# nrf5002 register map
Vendor: Nordic Semiconductor; Series: nRF50; File version: 1
CPU: CM0 r0p4, little endian, no MPU, no FPU, 2 interrupt priority bits, 32 interrupts
Registers are 32-bit, read-write, reset 0x0 unless marked. A register's access mark holds for its fields unless they carry their own. Offsets are from the block's base; [hi:lo] are bit positions; 'fields as' and 'values as' point back to an identical list.

## CCM — AES CCM mode encryption
Base 0x4000A000
0x00 TASKS_KSGEN wo — Start generation of keystream. This operation will stop by itself when completed.
  [0] TASKS_KSGEN
    1=Trigger task
0x04 TASKS_CRYPT wo — Start encryption/decryption. This operation will stop by itself when completed.
  [0] TASKS_CRYPT
    1=Trigger task
0x08 TASKS_STOP wo — Stop encryption/decryption
  [0] TASKS_STOP
    1=Trigger task
0x0C TASKS_RATEOVERRIDE wo — Override DATARATE setting in MODE register with the contents of the RATEOVERRIDE register for any ongoing encryption/decryption
  [0] TASKS_RATEOVERRIDE
    1=Trigger task
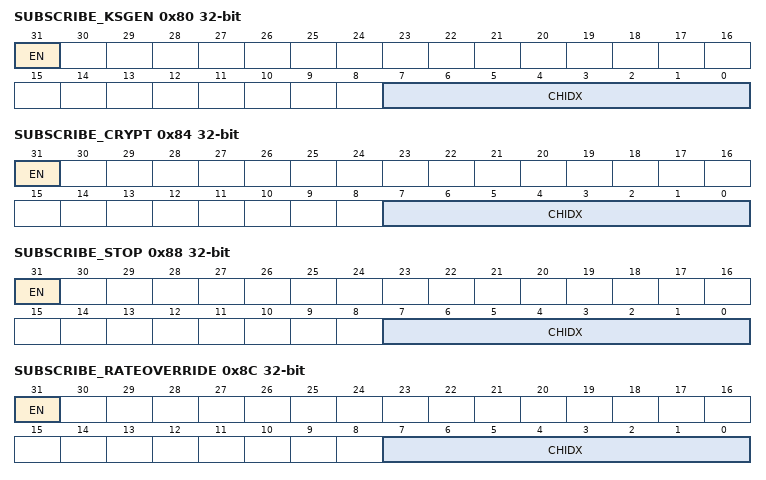
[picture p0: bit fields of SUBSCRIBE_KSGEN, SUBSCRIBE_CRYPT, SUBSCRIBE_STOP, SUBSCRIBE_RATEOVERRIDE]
0x80 SUBSCRIBE_KSGEN — Subscribe configuration for task KSGEN
  [31] EN
    0=Disabled (Disable subscription); 1=Enabled (Enable subscription)
  [7:0] CHIDX — DPPI channel that task KSGEN will subscribe to
0x84 SUBSCRIBE_CRYPT — Subscribe configuration for task CRYPT
  [31] EN
    values as SUBSCRIBE_KSGEN.EN
  [7:0] CHIDX — DPPI channel that task CRYPT will subscribe to
0x88 SUBSCRIBE_STOP — Subscribe configuration for task STOP
  [31] EN
    values as SUBSCRIBE_KSGEN.EN
  [7:0] CHIDX — DPPI channel that task STOP will subscribe to
0x8C SUBSCRIBE_RATEOVERRIDE — Subscribe configuration for task RATEOVERRIDE
  [31] EN
    values as SUBSCRIBE_KSGEN.EN
  [7:0] CHIDX — DPPI channel that task RATEOVERRIDE will subscribe to
0x100 EVENTS_ENDKSGEN — Keystream generation complete
  [0] EVENTS_ENDKSGEN
    0=NotGenerated (Event not generated); 1=Generated (Event generated)
0x104 EVENTS_ENDCRYPT — Encrypt/decrypt complete
  [0] EVENTS_ENDCRYPT
    values as EVENTS_ENDKSGEN.EVENTS_ENDKSGEN
0x108 EVENTS_ERROR — Deprecated register - CCM error event
  [0] EVENTS_ERROR — Deprecated field - CCM error event
    values as EVENTS_ENDKSGEN.EVENTS_ENDKSGEN
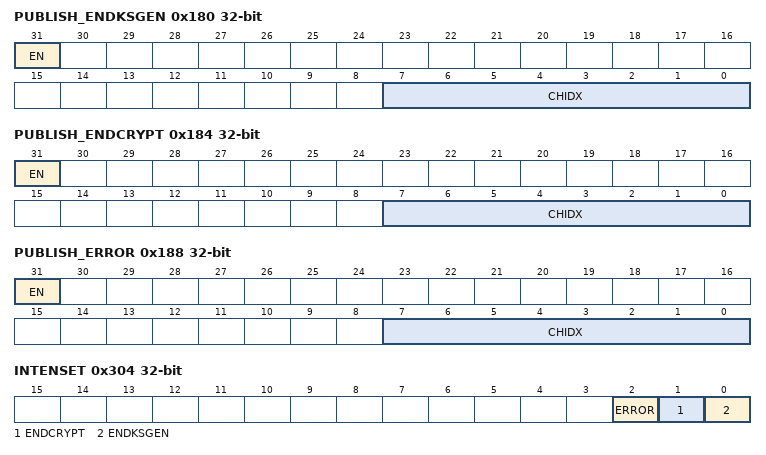
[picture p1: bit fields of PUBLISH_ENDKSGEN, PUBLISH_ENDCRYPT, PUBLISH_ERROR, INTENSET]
0x180 PUBLISH_ENDKSGEN — Publish configuration for event ENDKSGEN
  [31] EN
    0=Disabled (Disable publishing); 1=Enabled (Enable publishing)
  [7:0] CHIDX — DPPI channel that event ENDKSGEN will publish to
0x184 PUBLISH_ENDCRYPT — Publish configuration for event ENDCRYPT
  [31] EN
    values as PUBLISH_ENDKSGEN.EN
  [7:0] CHIDX — DPPI channel that event ENDCRYPT will publish to
0x188 PUBLISH_ERROR — Deprecated register - Publish configuration for event ERROR
  [31] EN
    values as PUBLISH_ENDKSGEN.EN
  [7:0] CHIDX — DPPI channel that event ERROR will publish to
0x200 SHORTS — Shortcuts between local events and tasks
  [0] ENDKSGEN_CRYPT — Shortcut between event ENDKSGEN and task CRYPT
    0=Disabled (Disable shortcut); 1=Enabled (Enable shortcut)
0x304 INTENSET — Enable interrupt
  [all] fields
    on read: 0=Disabled (Read: Disabled); 1=Enabled (Read: Enabled) | on write: 1=Set (Enable)
  [2] ERROR — Deprecated intsetfield - Write '1' to enable interrupt for event ERROR
  [1] ENDCRYPT — Write '1' to enable interrupt for event ENDCRYPT
  [0] ENDKSGEN — Write '1' to enable interrupt for event ENDKSGEN
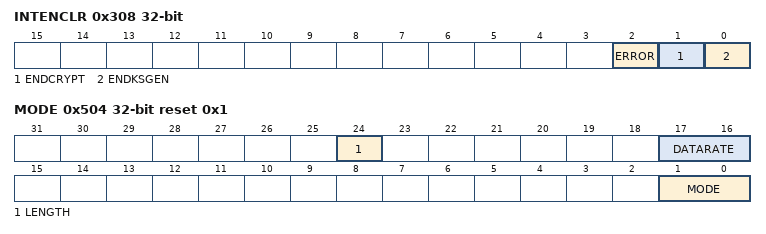
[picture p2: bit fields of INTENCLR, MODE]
0x308 INTENCLR — Disable interrupt
  [all] fields
    on read: 0=Disabled (Read: Disabled); 1=Enabled (Read: Enabled) | on write: 1=Clear (Disable)
  [2] ERROR — Deprecated intclrfield - Write '1' to disable interrupt for event ERROR
  [1] ENDCRYPT — Write '1' to disable interrupt for event ENDCRYPT
  [0] ENDKSGEN — Write '1' to disable interrupt for event ENDKSGEN
0x400 MICSTATUS ro — MIC check result
  [0] MICSTATUS — The result of the MIC check performed during the previous decryption operation
    0=CheckFailed (MIC check failed); 1=CheckPassed (MIC check passed)
0x500 ENABLE
  [1:0] ENABLE — Enable or disable CCM
    0=Disabled; 2=Enabled
0x504 MODE reset 0x1 — Operation mode
  [24] LENGTH — Packet length configuration
    0=Default length. Effective length of LENGTH field in encrypted/decrypted packet is 5 bits. A keystream for packet payloads up to 27 bytes will be generated.; 1=Extended length. Effective length of LENGTH field in encrypted/decrypted packet is 8 bits. A keystream for packet payloads up to MAXPACKETSIZE bytes will be generated.
  [17:16] DATARATE — Radio data rate that the CCM shall run synchronous with
    0=1Mbit (1 Mbps); 1=2Mbit (2 Mbps); 2=125Kbps; 3=500Kbps
  [1:0] MODE — The mode of operation to be used. Settings in this register apply whenever either the KSGEN task or the CRYPT task is triggered.
    0=Encryption (AES CCM packet encryption mode); 1=Decryption (AES CCM packet decryption mode); 2=FastDecryption (AES fast decrypt mode)
0x508 CNFPTR — Pointer to data structure holding the AES key and the NONCE vector
  [31:0] CNFPTR — Pointer to the data structure holding the AES key and the CCM NONCE vector (see table CCM data structure overview)
0x50C INPTR — Input pointer
0x510 OUTPTR — Output pointer
0x514 SCRATCHPTR — Pointer to data area used for temporary storage
  [31:0] SCRATCHPTR — Pointer to a scratch data area used for temporary storage during keystream generation, MIC generation and encryption/decryption.
0x518 MAXPACKETSIZE reset 0xFB — Length of keystream generated when MODE.LENGTH = Extended
  [7:0] MAXPACKETSIZE — Length of keystream generated when MODE.LENGTH = Extended. This value must be greater than or equal to the subsequent packet payload to be encrypted/decrypted.
0x51C RATEOVERRIDE — Data rate override setting.
  [1:0] RATEOVERRIDE — Data rate override setting
    0=1Mbit (1 Mbps); 1=2Mbit (2 Mbps); 2=125Kbps; 3=500Kbps
0xFFC POWER reset 0x1 — Peripheral power control
  [0] POWER — Peripheral power control. The peripheral and its registers will be reset to initial state by switching the peripheral off and then back on again. All POWER registers in AAR, CCM and ECB must be disabled to see a reset of any of those functions.
    0=Disabled (Peripheral is powered off); 1=Enabled (Peripheral is powered on)
